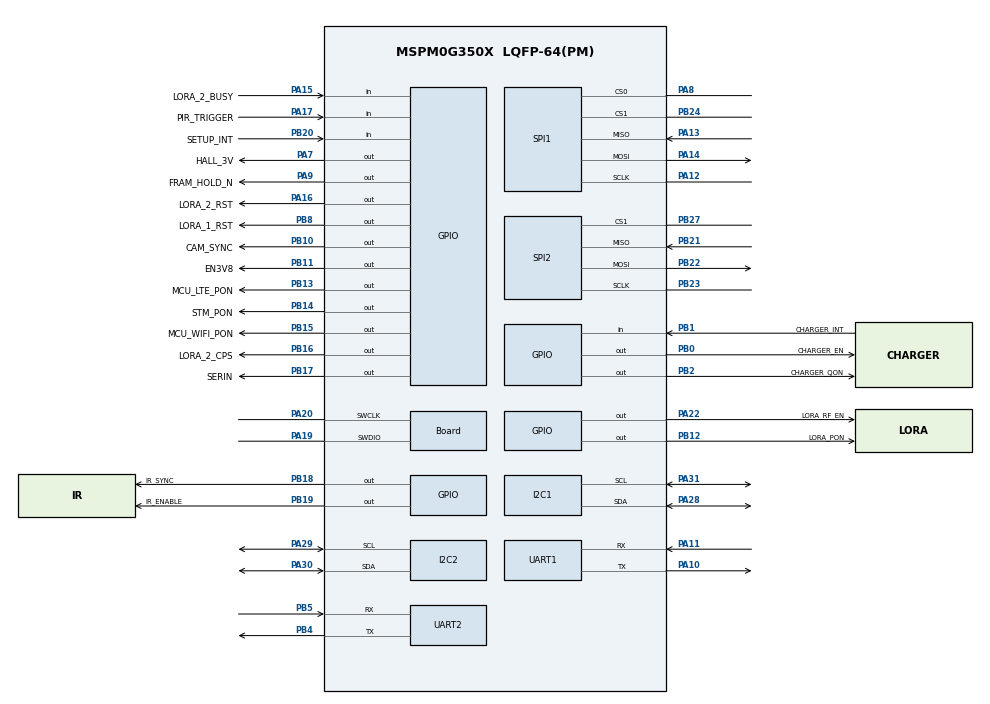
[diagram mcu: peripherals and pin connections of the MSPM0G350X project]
/**
 * @cliArgs --device "MSPM0G350X" --part "Default" --package "LQFP-64(PM)" --product "mspm0_sdk@2.08.00.02"
 * @versions {"tool":"1.25.0+4268"}
 */

/**
 * Import the modules used in this configuration.
 */
const Board  = scripting.addModule("/ti/driverlib/Board");
const GPIO   = scripting.addModule("/ti/driverlib/GPIO", {}, false);
const GPIO1  = GPIO.addInstance();
const GPIO2  = GPIO.addInstance();
const GPIO3  = GPIO.addInstance();
const I2C    = scripting.addModule("/ti/driverlib/I2C", {}, false);
const I2C1   = I2C.addInstance();
const I2C2   = I2C.addInstance();
const SPI    = scripting.addModule("/ti/driverlib/SPI", {}, false);
const SPI1   = SPI.addInstance();
const SPI2   = SPI.addInstance();
const SYSCTL = scripting.addModule("/ti/driverlib/SYSCTL");
const TIMER  = scripting.addModule("/ti/driverlib/TIMER", {}, false);
const TIMER1 = TIMER.addInstance();
const UART   = scripting.addModule("/ti/driverlib/UART", {}, false);
const UART1  = UART.addInstance();
const UART2  = UART.addInstance();

/**
 * Write custom configuration values to the imported modules.
 */
Board.peripheral.swclkPin.$assign = "PA20";
Board.peripheral.swdioPin.$assign = "PA19";

GPIO1.$name                                 = "EXTERNAL_INTERRUPT";
GPIO1.associatedPins.create(4);
GPIO1.associatedPins[0].$name               = "PIR_TRIGGER";
GPIO1.associatedPins[0].direction           = "INPUT";
GPIO1.associatedPins[0].ioStructure         = "SDW";
GPIO1.associatedPins[0].assignedPin         = "17";
GPIO1.associatedPins[0].assignedPort        = "PORTA";
GPIO1.associatedPins[0].assignedPortSegment = "Upper";
GPIO1.associatedPins[0].pin.$assign         = "PA17";
GPIO1.associatedPins[1].$name               = "CHARGER_INT";
GPIO1.associatedPins[1].direction           = "INPUT";
GPIO1.associatedPins[1].assignedPin         = "any";
GPIO1.associatedPins[1].ioStructure         = "SD";
GPIO1.associatedPins[1].interruptEn         = true;
GPIO1.associatedPins[1].polarity            = "RISE_FALL";
GPIO1.associatedPins[1].pin.$assign         = "PB1";
GPIO1.associatedPins[2].$name               = "LORA_2_BUSY";
GPIO1.associatedPins[2].direction           = "INPUT";
GPIO1.associatedPins[2].ioStructure         = "SD";
GPIO1.associatedPins[2].pin.$assign         = "PA15";
GPIO1.associatedPins[3].$name               = "SETUP_INT";
GPIO1.associatedPins[3].direction           = "INPUT";
GPIO1.associatedPins[3].assignedPort        = "PORTB";
GPIO1.associatedPins[3].assignedPin         = "any";
GPIO1.associatedPins[3].internalResistor    = "PULL_UP";
GPIO1.associatedPins[3].pin.$assign         = "PB20";

GPIO2.$name                          = "DIGITAL_OUTPUT_PORTB";
GPIO2.port                           = "PORTB";
GPIO2.associatedPins.create(14);
GPIO2.associatedPins[0].$name        = "CHARGER_EN";
GPIO2.associatedPins[0].ioStructure  = "SD";
GPIO2.associatedPins[0].assignedPin  = "0";
GPIO2.associatedPins[0].pin.$assign  = "PB0";
GPIO2.associatedPins[1].$name        = "CHARGER_QON";
GPIO2.associatedPins[1].ioStructure  = "SD";
GPIO2.associatedPins[1].assignedPin  = "2";
GPIO2.associatedPins[1].pin.$assign  = "PB2";
GPIO2.associatedPins[2].$name        = "LORA_1_RST";
GPIO2.associatedPins[2].ioStructure  = "SD";
GPIO2.associatedPins[2].assignedPin  = "8";
GPIO2.associatedPins[2].pin.$assign  = "PB8";
GPIO2.associatedPins[3].assignedPin  = "11";
GPIO2.associatedPins[3].ioStructure  = "SD";
GPIO2.associatedPins[3].$name        = "EN3V8";
GPIO2.associatedPins[3].pin.$assign  = "PB11";
GPIO2.associatedPins[4].$name        = "LORA_PON";
GPIO2.associatedPins[4].ioStructure  = "SD";
GPIO2.associatedPins[4].assignedPin  = "12";
GPIO2.associatedPins[4].pin.$assign  = "PB12";
GPIO2.associatedPins[5].$name        = "MCU_LTE_PON";
GPIO2.associatedPins[5].ioStructure  = "SD";
GPIO2.associatedPins[5].assignedPin  = "13";
GPIO2.associatedPins[5].pin.$assign  = "PB13";
GPIO2.associatedPins[6].$name        = "STM_PON";
GPIO2.associatedPins[6].ioStructure  = "SD";
GPIO2.associatedPins[6].assignedPin  = "14";
GPIO2.associatedPins[6].pin.$assign  = "PB14";
GPIO2.associatedPins[7].ioStructure  = "SD";
GPIO2.associatedPins[7].assignedPin  = "15";
GPIO2.associatedPins[7].$name        = "MCU_WIFI_PON";
GPIO2.associatedPins[7].pin.$assign  = "PB15";
GPIO2.associatedPins[8].$name        = "SERIN";
GPIO2.associatedPins[8].ioStructure  = "SD";
GPIO2.associatedPins[8].assignedPin  = "17";
GPIO2.associatedPins[8].pin.$assign  = "PB17";
GPIO2.associatedPins[9].assignedPin  = "18";
GPIO2.associatedPins[9].ioStructure  = "SD";
GPIO2.associatedPins[9].$name        = "IR_SYNC";
GPIO2.associatedPins[9].pin.$assign  = "PB18";
GPIO2.associatedPins[10].$name       = "IR_ENABLE";
GPIO2.associatedPins[10].ioStructure = "SD";
GPIO2.associatedPins[10].assignedPin = "19";
GPIO2.associatedPins[10].pin.$assign = "PB19";
GPIO2.associatedPins[11].$name       = "CAM_SYNC";
GPIO2.associatedPins[11].ioStructure = "SD";
GPIO2.associatedPins[11].assignedPin = "10";
GPIO2.associatedPins[11].pin.$assign = "PB10";
GPIO2.associatedPins[12].$name       = "GAUGE_EN";
GPIO2.associatedPins[13].$name       = "LORA_2_CPS";
GPIO2.associatedPins[13].pin.$assign = "PB16";

GPIO3.$name                         = "DIGITAL_OUTPUT_PORTA";
GPIO3.port                          = "PORTA";
GPIO3.associatedPins.create(4);
GPIO3.associatedPins[0].$name       = "LORA_RF_EN";
GPIO3.associatedPins[0].ioStructure = "SD";
GPIO3.associatedPins[0].assignedPin = "22";
GPIO3.associatedPins[0].pin.$assign = "PA22";
GPIO3.associatedPins[1].$name       = "FRAM_HOLD_N";
GPIO3.associatedPins[1].assignedPin = "9";
GPIO3.associatedPins[1].ioStructure = "HS";
GPIO3.associatedPins[1].pin.$assign = "PA9";
GPIO3.associatedPins[2].$name       = "LORA_2_RST";
GPIO3.associatedPins[2].pin.$assign = "PA16";
GPIO3.associatedPins[3].$name       = "HALL_3V";
GPIO3.associatedPins[3].pin.$assign = "PA7";

I2C1.$name                         = "I2C_0";
I2C1.basicEnableController         = true;
I2C1.intController                 = ["ARBITRATION_LOST","NACK","RXFIFO_TRIGGER","RX_DONE","TXFIFO_TRIGGER","TX_DONE"];
I2C1.peripheral.$assign            = "I2C0";
I2C1.peripheral.sdaPin.$assign     = "PA28";
I2C1.peripheral.sclPin.$assign     = "PA31";
I2C1.sdaPinConfig.$name            = "ti_driverlib_gpio_GPIOPinGeneric9";
I2C1.sdaPinConfig.internalResistor = "PULL_UP";
I2C1.sclPinConfig.$name            = "ti_driverlib_gpio_GPIOPinGeneric10";
I2C1.sclPinConfig.internalResistor = "PULL_UP";

I2C2.$name                         = "I2C_1";
I2C2.basicEnableController         = true;
I2C2.intController                 = ["ARBITRATION_LOST","NACK","RXFIFO_TRIGGER","RX_DONE","TXFIFO_TRIGGER","TX_DONE"];
I2C2.peripheral.$assign            = "I2C1";
I2C2.peripheral.sdaPin.$assign     = "PA30";
I2C2.peripheral.sclPin.$assign     = "PA29";
I2C2.sdaPinConfig.$name            = "ti_driverlib_gpio_GPIOPinGeneric11";
I2C2.sdaPinConfig.internalResistor = "PULL_UP";
I2C2.sclPinConfig.$name            = "ti_driverlib_gpio_GPIOPinGeneric12";
I2C2.sclPinConfig.internalResistor = "PULL_UP";

SPI1.$name                      = "SPI_0";
SPI1.enableDMAEvent1            = false;
SPI1.enableDMAEvent2            = false;
SPI1.chipSelect                 = ["0","1"];
SPI1.sclkPinConfig.$name        = "ti_driverlib_gpio_GPIOPinGeneric0";
SPI1.mosiPinConfig.$name        = "ti_driverlib_gpio_GPIOPinGeneric1";
SPI1.misoPinConfig.$name        = "ti_driverlib_gpio_GPIOPinGeneric2";
SPI1.cs0PinConfig.$name         = "ti_driverlib_gpio_GPIOPinGeneric3";
SPI1.peripheral.$assign         = "SPI0";
SPI1.peripheral.sclkPin.$assign = "PA12";
SPI1.peripheral.mosiPin.$assign = "PA14";
SPI1.peripheral.misoPin.$assign = "PA13";
SPI1.peripheral.cs0Pin.$assign  = "PA8";
SPI1.peripheral.cs1Pin.$assign  = "PB24";
SPI1.cs1PinConfig.$name         = "ti_driverlib_gpio_GPIOPinGeneric4";

SPI2.$name                              = "SPI_1";
SPI2.enableDMAEvent1                    = false;
SPI2.enableDMAEvent2                    = false;
SPI2.targetBitRate                      = 1000000;
SPI2.chipSelect                         = [];
SPI2.mode                               = "PERIPHERAL";
SPI2.peripheralChipSelect               = "1";
SPI2.sclkPinConfig.onlyInternalResistor = scripting.forceWrite(false);
SPI2.sclkPinConfig.passedPeripheralType = scripting.forceWrite("Digital");
SPI2.sclkPinConfig.$name                = "ti_driverlib_gpio_GPIOPinGeneric5";
SPI2.mosiPinConfig.hideOutputInversion  = scripting.forceWrite(false);
SPI2.mosiPinConfig.onlyInternalResistor = scripting.forceWrite(false);
SPI2.mosiPinConfig.passedPeripheralType = scripting.forceWrite("Digital");
SPI2.mosiPinConfig.$name                = "ti_driverlib_gpio_GPIOPinGeneric6";
SPI2.misoPinConfig.onlyInternalResistor = scripting.forceWrite(false);
SPI2.misoPinConfig.passedPeripheralType = scripting.forceWrite("Digital");
SPI2.misoPinConfig.$name                = "ti_driverlib_gpio_GPIOPinGeneric7";
SPI2.peripheral.$assign                 = "SPI1";
SPI2.peripheral.sclkPin.$assign         = "PB23";
SPI2.peripheral.mosiPin.$assign         = "PB22";
SPI2.peripheral.misoPin.$assign         = "PB21";
SPI2.peripheral.cs1Pin.$assign          = "PB27";
SPI2.cs1PinConfig.$name                 = "ti_driverlib_gpio_GPIOPinGeneric8";

SYSCTL.forceDefaultClkConfig = true;
SYSCTL.peripheral.$assign    = "SYSCTL";

TIMER1.$name              = "TIMER_0";
TIMER1.profile            = "Basic_Periodic";
TIMER1.peripheral.$assign = "TIMG8";

UART1.$name                    = "UART_0";
UART1.targetBaudRate           = 115200;
UART1.enabledInterrupts        = ["RX","TX"];
UART1.peripheral.$assign       = "UART0";
UART1.peripheral.rxPin.$assign = "PA11";
UART1.peripheral.txPin.$assign = "PA10";
UART1.txPinConfig.$name        = "ti_driverlib_gpio_GPIOPinGeneric13";
UART1.rxPinConfig.$name        = "ti_driverlib_gpio_GPIOPinGeneric14";

UART2.$name                            = "MCU_UART_1";
UART2.peripheral.$assign               = "UART1";
UART2.peripheral.rxPin.$assign         = "PB5";
UART2.peripheral.txPin.$assign         = "PB4";
UART2.txPinConfig.direction            = scripting.forceWrite("OUTPUT");
UART2.txPinConfig.hideOutputInversion  = scripting.forceWrite(false);
UART2.txPinConfig.onlyInternalResistor = scripting.forceWrite(false);
UART2.txPinConfig.passedPeripheralType = scripting.forceWrite("Digital");
UART2.txPinConfig.$name                = "ti_driverlib_gpio_GPIOPinGeneric15";
UART2.rxPinConfig.hideOutputInversion  = scripting.forceWrite(false);
UART2.rxPinConfig.onlyInternalResistor = scripting.forceWrite(false);
UART2.rxPinConfig.passedPeripheralType = scripting.forceWrite("Digital");
UART2.rxPinConfig.$name                = "ti_driverlib_gpio_GPIOPinGeneric16";

/**
 * Pinmux solution for unlocked pins/peripherals. This ensures that minor changes to the automatic solver in a future
 * version of the tool will not impact the pinmux you originally saw.  These lines can be completely deleted in order to
 * re-solve from scratch.
 */
Board.peripheral.$suggestSolution             = "DEBUGSS";
GPIO2.associatedPins[12].pin.$suggestSolution = "PB25";
